# PIC32CM5164LE00048 register map
Vendor: Microchip Technology; Series: PIC32CMLE00; File version: 0
CPU: CM23 r0p0, selectable endian, MPU, no FPU, 2 interrupt priority bits
Registers are 32-bit, read-write, reset 0x0 unless marked. A register's access mark holds for its fields unless they carry their own. Offsets are from the block's base; [hi:lo] are bit positions; {n}, {i} and the like mark numbered series; 'fields as' and 'values as' point back to an identical list.

## SysTick — SysTick Timer
Base 0xE000E010; register names take the prefix SysTick_
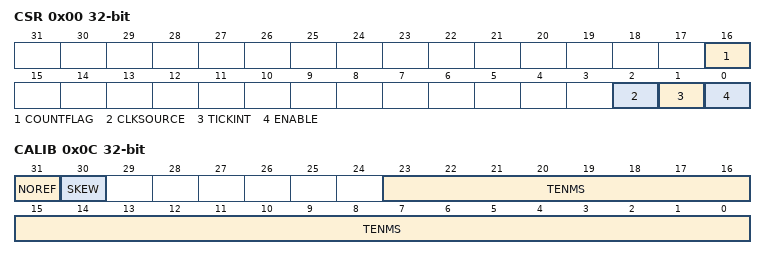
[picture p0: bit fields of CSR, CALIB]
0x00 CSR — SysTick Control and Status Register
  [16] COUNTFLAG
  [2] CLKSOURCE — Clock source
  [1] TICKINT — Tick interrupt
  [0] ENABLE — SysTick enable
0x04 RVR — SysTick Reload Value Register
  [24] RELOAD — Counter reload value
0x08 CVR — SysTick Current Value Register
  [24] CURRENT — Current counter value
0x0C CALIB ro — SysTick Calibration Value Register
  [31] NOREF — No reference
  [30] SKEW
  [23:0] TENMS — Ten milliseconds

## TRAM — TrustRAM
Base 0x42005400; register names take the prefix TRAM_
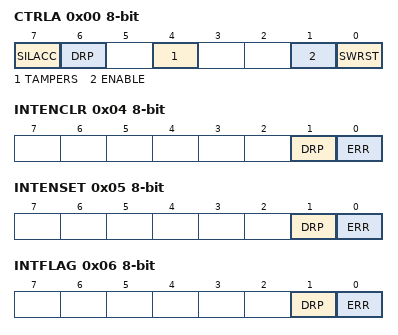
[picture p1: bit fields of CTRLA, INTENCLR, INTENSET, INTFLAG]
0x00 CTRLA 8-bit — Control
  [7] SILACC — Silent Access
  [6] DRP — Data Remanence Prevention
  [4] TAMPERS — Tamper Erase
  [1] ENABLE
  [0] SWRST — Software Reset
0x04 INTENCLR 8-bit — Interrupt Enable Clear
  [1] DRP — Data Remanence Prevention Ended Interrupt Enable
  [0] ERR — TrustRAM Readout Error Interrupt Enable
0x05 INTENSET 8-bit — Interrupt Enable Set
  fields as INTENCLR
0x06 INTFLAG 8-bit — Interrupt Flag Status and Clear
  [1] DRP — Data Remanence Prevention Ended
  [0] ERR — TrustRAM Readout Error
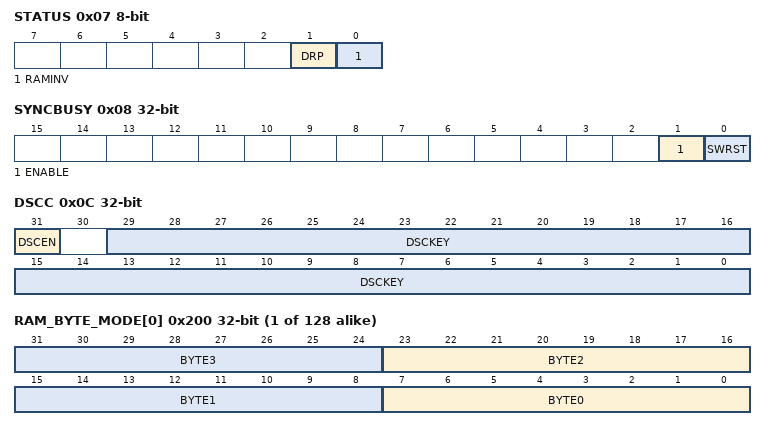
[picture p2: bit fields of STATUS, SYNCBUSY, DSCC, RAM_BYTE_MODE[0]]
0x07 STATUS 8-bit ro
  [1] DRP — Data Remanence Prevention Ongoing
  [0] RAMINV — RAM Inversion Bit
0x08 SYNCBUSY ro — Synchronization Busy Status
  [1] ENABLE — Enable Busy
  [0] SWRST — Software Reset Busy
0x0C DSCC wo — Data Scramble Control
  [31] DSCEN — Data Scramble Enable
  [29:0] DSCKEY — Data Scramble Key
{0x200+4i} RAM[{i}] (i=0..127) — TrustRAM
  [31:0] DATA — Trust RAM Data
{0x200+4i} RAM_BYTE_MODE[{i}] (i=0..127) (alternate view of RAM[{i}]) — TrustRAM
  [8n+7:8n] BYTE{n} (n=0..3) — Trust RAM Data
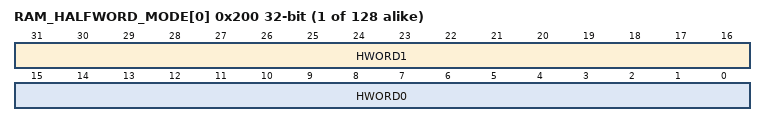
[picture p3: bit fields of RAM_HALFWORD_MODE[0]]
{0x200+4i} RAM_HALFWORD_MODE[{i}] (i=0..127) (alternate view of RAM[{i}]) — TrustRAM
  [31:16] HWORD1 — Trust RAM Halfword Data
  [15:0] HWORD0 — Trust RAM Halfword Data

## TRNG — True Random Generator
Base 0x42004400; register names take the prefix TRNG_
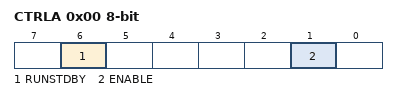
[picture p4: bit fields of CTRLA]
0x00 CTRLA 8-bit — Control A
  [6] RUNSTDBY — Run in Standby
  [1] ENABLE
0x04 EVCTRL 8-bit — Event Control
  [0] DATARDYEO — Data Ready Event Output
0x08 INTENCLR 8-bit — Interrupt Enable Clear
  [0] DATARDY — Data Ready Interrupt Enable
0x09 INTENSET 8-bit — Interrupt Enable Set
  [0] DATARDY — Data Ready Interrupt Enable
0x0A INTFLAG 8-bit — Interrupt Flag Status and Clear
  [0] DATARDY — Data Ready Interrupt Flag
0x20 DATA ro — Output Data

## WDT — Watchdog Timer
Base 0x40002000; register names take the prefix WDT_
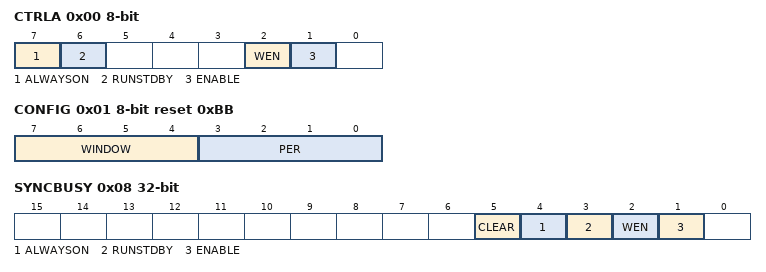
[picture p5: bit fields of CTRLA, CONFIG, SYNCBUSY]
0x00 CTRLA 8-bit — Control
  [7] ALWAYSON
  [6] RUNSTDBY — Run During Standby
  [2] WEN — Watchdog Timer Window Mode Enable
  [1] ENABLE
0x01 CONFIG 8-bit reset 0xBB — Configuration
  [7:4] WINDOW — Window Mode Time-Out Period
    0=CYC8 (8 clock cycles); 1=CYC16 (16 clock cycles); 2=CYC32 (32 clock cycles); 3=CYC64 (64 clock cycles); 4=CYC128 (128 clock cycles); 5=CYC256 (256 clock cycles); 6=CYC512 (512 clock cycles); 7=CYC1024 (1024 clock cycles); 8=CYC2048 (2048 clock cycles); 9=CYC4096 (4096 clock cycles); 10=CYC8192 (8192 clock cycles); 11=CYC16384 (16384 clock cycles)
  [3:0] PER — Time-Out Period
    values as WINDOW
0x02 EWCTRL 8-bit reset 0xB — Early Warning Interrupt Control
  [3:0] EWOFFSET — Early Warning Interrupt Time Offset
    0=CYC8 (8 clock cycles); 1=CYC16 (16 clock cycles); 2=CYC32 (32 clock cycles); 3=CYC64 (64 clock cycles); 4=CYC128 (128 clock cycles); 5=CYC256 (256 clock cycles); 6=CYC512 (512 clock cycles); 7=CYC1024 (1024 clock cycles); 8=CYC2048 (2048 clock cycles); 9=CYC4096 (4096 clock cycles); 10=CYC8192 (8192 clock cycles)
0x04 INTENCLR 8-bit — Interrupt Enable Clear
  [0] EW — Early Warning Interrupt Enable
0x05 INTENSET 8-bit — Interrupt Enable Set
  [0] EW — Early Warning Interrupt Enable
0x06 INTFLAG 8-bit — Interrupt Flag Status and Clear
  [0] EW — Early Warning
0x08 SYNCBUSY ro — Synchronization Busy
  [5] CLEAR — Clear Synchronization Busy
  [4] ALWAYSON — Always-On Synchronization Busy
  [3] RUNSTDBY — Run During Standby Synchronization Busy
  [2] WEN — Window Enable Synchronization Busy
  [1] ENABLE — Enable Synchronization Busy
0x0C CLEAR 8-bit wo
  [7:0] CLEAR — Watchdog Clear
    165=KEY (Clear Key)

## Notices in the file
Copyright (c) 2017 Microchip Technology Inc.
SPDX-License-Identifier: Apache-2.0
Licensed under the Apache License, Version 2.0 (the "License");
you may not use this file except in compliance with the License.
You may obtain a copy of the License at
http://www.apache.org/licenses/LICENSE-2.0
Unless required by applicable law or agreed to in writing, software
distributed under the License is distributed on an "AS IS" BASIS,
WITHOUT WARRANTIES OR CONDITIONS OF ANY KIND, either express or implied.
See the License for the specific language governing permissions and
limitations under the License.
